AUTOSAR XML (schema 4-3-0)
package /E3_1_2_Premium
  system System
    system mapping Mapping_TestSwc_RGS_VL_Data
      data-mappings:
        data-element=Geltungsbereich_E3_1_2_Premium.R_RGS_Nachlauf_allg.RGS_Nachlauf_allg, system-signal=RGS_Nachlauf_allg
        data-element=Geltungsbereich_E3_1_2_Premium.R_RGS_VL_Nachlauf_2.RGS_VL_Nachlauf_2, system-signal=RGS_VL_Nachlauf_2
        data-element=Geltungsbereich_E3_1_2_Premium.R_NM_Airbag_01_FCAB.NM_Airbag_01_FCAB, system-signal=NM_Airbag_01_FCAB
        data-element=Geltungsbereich_E3_1_2_Premium.R_RGS_VL_Anforderung.RGS_VL_Anforderung, system-signal=RGS_VL_Anforderung
        data-element=Geltungsbereich_E3_1_2_Premium.P_RGS_VL_KD_Fehler.RGS_VL_KD_Fehler, system-signal=RGS_VL_KD_Fehler
        data-element=Geltungsbereich_E3_1_2_Premium.P_NM_RGS_VL_NM_aktiv_KL15.NM_RGS_VL_NM_aktiv_KL15, system-signal=NM_RGS_VL_NM_aktiv_KL15
        data-element=Geltungsbereich_E3_1_2_Premium.P_NM_RGS_VL_CBV_AWB.NM_RGS_VL_CBV_AWB, system-signal=NM_RGS_VL_CBV_AWB
        data-element=Geltungsbereich_E3_1_2_Premium.P_NM_RGS_VL_NM_aktiv_Tmin.NM_RGS_VL_NM_aktiv_Tmin, system-signal=NM_RGS_VL_NM_aktiv_Tmin
        data-element=Geltungsbereich_E3_1_2_Premium.P_NM_RGS_VL_CBV_CRI.NM_RGS_VL_CBV_CRI, system-signal=NM_RGS_VL_CBV_CRI
        data-element=Geltungsbereich_E3_1_2_Premium.P_NM_RGS_VL_UDS_CC.NM_RGS_VL_UDS_CC, system-signal=NM_RGS_VL_UDS_CC
        data-element=Geltungsbereich_E3_1_2_Premium.P_NM_RGS_VL_NM_State.NM_RGS_VL_NM_State, system-signal=NM_RGS_VL_NM_State
        data-element=Geltungsbereich_E3_1_2_Premium.P_RGS_VL_Lokalaktiv.RGS_VL_Lokalaktiv, system-signal=RGS_VL_Lokalaktiv
        data-element=Geltungsbereich_E3_1_2_Premium.P_RGS_VL_KompSchutz.RGS_VL_KompSchutz, system-signal=RGS_VL_KompSchutz
        data-element=Geltungsbereich_E3_1_2_Premium.P_RGS_VL_Abschaltstufe.RGS_VL_Abschaltstufe, system-signal=RGS_VL_Abschaltstufe
        data-element=Geltungsbereich_E3_1_2_Premium.P_NM_RGS_VL_Wakeup.NM_RGS_VL_Wakeup, system-signal=NM_RGS_VL_Wakeup
        data-element=Geltungsbereich_E3_1_2_Premium.P_RGS_VL_Subsystemaktiv.RGS_VL_Subsystemaktiv, system-signal=RGS_VL_Subsystemaktiv
        data-element=Geltungsbereich_E3_1_2_Premium.P_RGS_VL_Transport_Mode.RGS_VL_Transport_Mode, system-signal=RGS_VL_Transport_Mode
        data-element=Geltungsbereich_E3_1_2_Premium.P_RGS_VL_Nachlauftyp.RGS_VL_Nachlauftyp, system-signal=RGS_VL_Nachlauftyp
        data-element=Geltungsbereich_E3_1_2_Premium.P_RGS_VL_Gurtgeschwindigkeit.RGS_VL_Gurtgeschwindigkeit, system-signal=RGS_VL_Gurtgeschwindigkeit
        data-element=Geltungsbereich_E3_1_2_Premium.P_RGS_VL_Gurtbandauszug.RGS_VL_Gurtbandauszug, system-signal=RGS_VL_Gurtbandauszug
        data-element=Geltungsbereich_E3_1_2_Premium.P_NM_RGS_VL_NM_aktiv_Mot_aktiv.NM_RGS_VL_NM_aktiv_Mot_aktiv, system-signal=NM_RGS_VL_NM_aktiv_Mot_aktiv
        data-element=Geltungsbereich_E3_1_2_Premium.P_NM_RGS_VL_NM_aktiv_Diag.NM_RGS_VL_NM_aktiv_Diag, system-signal=NM_RGS_VL_NM_aktiv_Diag
        data-element=Geltungsbereich_E3_1_2_Premium.P_NM_RGS_VL_FCIB.NM_RGS_VL_FCIB, system-signal=NM_RGS_VL_FCIB
        data-element=Geltungsbereich_E3_1_2_Premium.P_NM_RGS_VL_FCAB.NM_RGS_VL_FCAB, system-signal=NM_RGS_VL_FCAB
        data-element=Geltungsbereich_E3_1_2_Premium.P_RGS_VL_SNI_10.RGS_VL_SNI_10, system-signal=RGS_VL_SNI_10
        data-element=Geltungsbereich_E3_1_2_Premium.P_KN_RGS_VL_ECUKnockOutTimer.KN_RGS_VL_ECUKnockOutTimer, system-signal=KN_RGS_VL_ECUKnockOutTimer
        data-element=Geltungsbereich_E3_1_2_Premium.P_KN_RGS_VL_BusKnockOut.KN_RGS_VL_BusKnockOut, system-signal=KN_RGS_VL_BusKnockOut
        data-element=Geltungsbereich_E3_1_2_Premium.P_KN_RGS_VL_ECUKnockOut.KN_RGS_VL_ECUKnockOut, system-signal=KN_RGS_VL_ECUKnockOut
        data-element=Geltungsbereich_E3_1_2_Premium.P_KN_RGS_VL_BusKnockOutTimer.KN_RGS_VL_BusKnockOutTimer, system-signal=KN_RGS_VL_BusKnockOutTimer
        data-element=Geltungsbereich_E3_1_2_Premium.P_NM_RGS_VL_SNI_10.NM_RGS_VL_SNI_10, system-signal=NM_RGS_VL_SNI_10
        data-element=Geltungsbereich_E3_1_2_Premium.P_RGS_VL_keineStraffungUnterspg.RGS_VL_keineStraffungUnterspg, system-signal=RGS_VL_keineStraffungUnterspg
        data-element=Geltungsbereich_E3_1_2_Premium.P_RGS_VL_nicht_programmiert.RGS_VL_nicht_programmiert, system-signal=RGS_VL_nicht_programmiert
        data-element=Geltungsbereich_E3_1_2_Premium.P_RGS_VL_Uebertemperatur_defekt.RGS_VL_Uebertemperatur_defekt, system-signal=RGS_VL_Uebertemperatur_defekt
        data-element=Geltungsbereich_E3_1_2_Premium.P_RGS_VL_Bauteilfehler.RGS_VL_Bauteilfehler, system-signal=RGS_VL_Bauteilfehler
        data-element=Geltungsbereich_E3_1_2_Premium.P_RGS_VL_keineStraffungUeberspg.RGS_VL_keineStraffungUeberspg, system-signal=RGS_VL_keineStraffungUeberspg
        data-element=Geltungsbereich_E3_1_2_Premium.P_RGS_VL_Max_Gurtlosezyklen.RGS_VL_Max_Gurtlosezyklen, system-signal=RGS_VL_Max_Gurtlosezyklen
        data-element=Geltungsbereich_E3_1_2_Premium.P_RGS_VL_Temp.RGS_VL_Temp, system-signal=RGS_VL_Temp
        data-element=Geltungsbereich_E3_1_2_Premium.P_RGS_VL_Kommunikationsfehler_ASG.RGS_VL_Kommunikationsfehler_ASG, system-signal=RGS_VL_Kommunikationsfehler_ASG
        data-element=Geltungsbereich_E3_1_2_Premium.P_RGS_VL_Unterspannung.RGS_VL_Unterspannung, system-signal=RGS_VL_Unterspannung
        data-element=Geltungsbereich_E3_1_2_Premium.P_RGS_VL_Max_Straffzyklenfehler.RGS_VL_Max_Straffzyklenfehler, system-signal=RGS_VL_Max_Straffzyklenfehler
        data-element=Geltungsbereich_E3_1_2_Premium.P_RGS_VL_Max_Haptikzyklenfehler.RGS_VL_Max_Haptikzyklenfehler, system-signal=RGS_VL_Max_Haptikzyklenfehler
        data-element=Geltungsbereich_E3_1_2_Premium.P_RGS_VL_Crashabschaltung.RGS_VL_Crashabschaltung, system-signal=RGS_VL_Crashabschaltung
        data-element=Geltungsbereich_E3_1_2_Premium.P_RGS_VL_Ueberspannung.RGS_VL_Ueberspannung, system-signal=RGS_VL_Ueberspannung
        data-element=Geltungsbereich_E3_1_2_Premium.P_RGS_VL_Motorfehler.RGS_VL_Motorfehler, system-signal=RGS_VL_Motorfehler
        data-element=Geltungsbereich_E3_1_2_Premium.P_RGS_VL_EEPROM_Datensatzfehler.RGS_VL_EEPROM_Datensatzfehler, system-signal=RGS_VL_EEPROM_Datensatzfehler
        data-element=Geltungsbereich_E3_1_2_Premium.P_RGS_VL_InPos.RGS_VL_InPos, system-signal=RGS_VL_InPos
        data-element=Geltungsbereich_E3_1_2_Premium.P_RGS_VL_Strom.RGS_VL_Strom, system-signal=RGS_VL_Strom
        data-element=Geltungsbereich_E3_1_2_Premium.P_RGS_VL_Status.RGS_VL_Status, system-signal=RGS_VL_Status
package /ComponentTypes
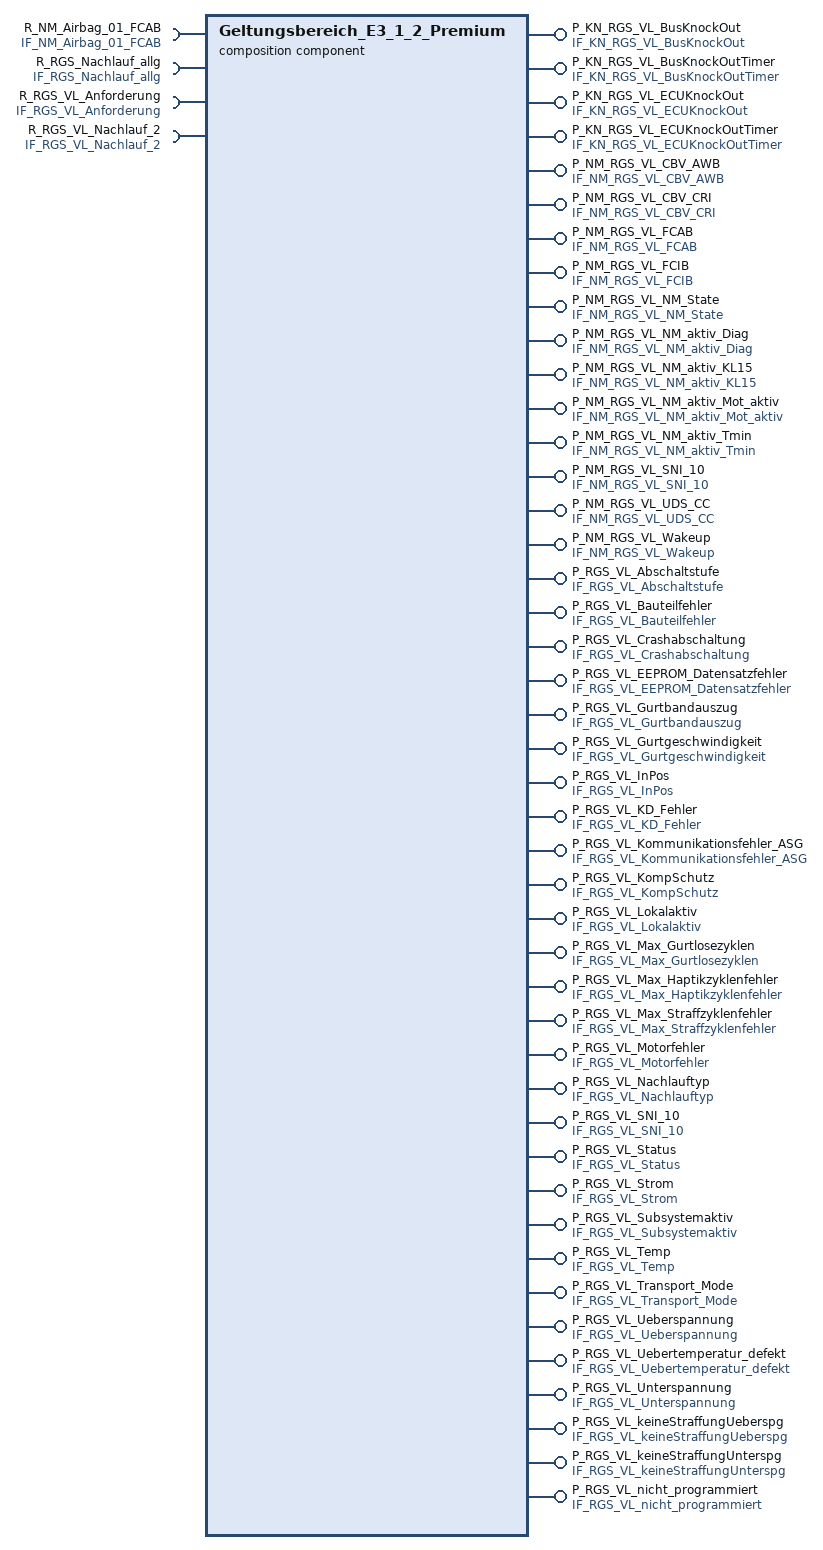
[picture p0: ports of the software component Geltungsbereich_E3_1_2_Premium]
  composition sw component type Geltungsbereich_E3_1_2_Premium
    44 x provide port:
      P_KN_RGS_VL_BusKnockOut: nonqueued-sender-com-spec{data-element=KN_RGS_VL_BusKnockOut, handle-out-of-range=DEFAULT, init-value=constant-reference=Init_KN_RGS_VL_BusKnockOut}, provided-interface=IF_KN_RGS_VL_BusKnockOut
      P_KN_RGS_VL_BusKnockOutTimer: nonqueued-sender-com-spec{data-element=KN_RGS_VL_BusKnockOutTimer, handle-out-of-range=DEFAULT, init-value=constant-reference=Init_KN_RGS_VL_BusKnockOutTimer}, provided-interface=IF_KN_RGS_VL_BusKnockOutTimer
      P_KN_RGS_VL_ECUKnockOut: nonqueued-sender-com-spec{data-element=KN_RGS_VL_ECUKnockOut, handle-out-of-range=DEFAULT, init-value=constant-reference=Init_KN_RGS_VL_ECUKnockOut}, provided-interface=IF_KN_RGS_VL_ECUKnockOut
      P_KN_RGS_VL_ECUKnockOutTimer: nonqueued-sender-com-spec{data-element=KN_RGS_VL_ECUKnockOutTimer, handle-out-of-range=DEFAULT, init-value=constant-reference=Init_KN_RGS_VL_ECUKnockOutTimer}, provided-interface=IF_KN_RGS_VL_ECUKnockOutTimer
      P_NM_RGS_VL_CBV_AWB: nonqueued-sender-com-spec{data-element=NM_RGS_VL_CBV_AWB, handle-out-of-range=DEFAULT, init-value=constant-reference=Init_NM_RGS_VL_CBV_AWB}, provided-interface=IF_NM_RGS_VL_CBV_AWB
      P_NM_RGS_VL_CBV_CRI: nonqueued-sender-com-spec{data-element=NM_RGS_VL_CBV_CRI, handle-out-of-range=DEFAULT, init-value=constant-reference=Init_NM_RGS_VL_CBV_CRI}, provided-interface=IF_NM_RGS_VL_CBV_CRI
      P_NM_RGS_VL_FCAB: nonqueued-sender-com-spec{data-element=NM_RGS_VL_FCAB, handle-out-of-range=DEFAULT, init-value=constant-reference=Init_NM_RGS_VL_FCAB}, provided-interface=IF_NM_RGS_VL_FCAB
      P_NM_RGS_VL_FCIB: nonqueued-sender-com-spec{data-element=NM_RGS_VL_FCIB, handle-out-of-range=DEFAULT, init-value=constant-reference=Init_NM_RGS_VL_FCIB}, provided-interface=IF_NM_RGS_VL_FCIB
      P_NM_RGS_VL_NM_State: nonqueued-sender-com-spec{data-element=NM_RGS_VL_NM_State, handle-out-of-range=DEFAULT, init-value=constant-reference=Init_NM_RGS_VL_NM_State}, provided-interface=IF_NM_RGS_VL_NM_State
      P_NM_RGS_VL_NM_aktiv_Diag: nonqueued-sender-com-spec{data-element=NM_RGS_VL_NM_aktiv_Diag, handle-out-of-range=DEFAULT, init-value=constant-reference=Init_NM_RGS_VL_NM_aktiv_Diag}, provided-interface=IF_NM_RGS_VL_NM_aktiv_Diag
      P_NM_RGS_VL_NM_aktiv_KL15: nonqueued-sender-com-spec{data-element=NM_RGS_VL_NM_aktiv_KL15, handle-out-of-range=DEFAULT, init-value=constant-reference=Init_NM_RGS_VL_NM_aktiv_KL15}, provided-interface=IF_NM_RGS_VL_NM_aktiv_KL15
      P_NM_RGS_VL_NM_aktiv_Mot_aktiv: nonqueued-sender-com-spec{data-element=NM_RGS_VL_NM_aktiv_Mot_aktiv, handle-out-of-range=DEFAULT, init-value=constant-reference=Init_NM_RGS_VL_NM_aktiv_Mot_aktiv}, provided-interface=IF_NM_RGS_VL_NM_aktiv_Mot_aktiv
      P_NM_RGS_VL_NM_aktiv_Tmin: nonqueued-sender-com-spec{data-element=NM_RGS_VL_NM_aktiv_Tmin, handle-out-of-range=DEFAULT, init-value=constant-reference=Init_NM_RGS_VL_NM_aktiv_Tmin}, provided-interface=IF_NM_RGS_VL_NM_aktiv_Tmin
      P_NM_RGS_VL_SNI_10: nonqueued-sender-com-spec{data-element=NM_RGS_VL_SNI_10, handle-out-of-range=DEFAULT, init-value=constant-reference=Init_NM_RGS_VL_SNI_10}, provided-interface=IF_NM_RGS_VL_SNI_10
      P_NM_RGS_VL_UDS_CC: nonqueued-sender-com-spec{data-element=NM_RGS_VL_UDS_CC, handle-out-of-range=DEFAULT, init-value=constant-reference=Init_NM_RGS_VL_UDS_CC}, provided-interface=IF_NM_RGS_VL_UDS_CC
      P_NM_RGS_VL_Wakeup: nonqueued-sender-com-spec{data-element=NM_RGS_VL_Wakeup, handle-out-of-range=DEFAULT, init-value=constant-reference=Init_NM_RGS_VL_Wakeup}, provided-interface=IF_NM_RGS_VL_Wakeup
      P_RGS_VL_Abschaltstufe: nonqueued-sender-com-spec{data-element=RGS_VL_Abschaltstufe, handle-out-of-range=DEFAULT, init-value=constant-reference=Init_RGS_VL_Abschaltstufe}, provided-interface=IF_RGS_VL_Abschaltstufe
      P_RGS_VL_Bauteilfehler: nonqueued-sender-com-spec{data-element=RGS_VL_Bauteilfehler, handle-out-of-range=DEFAULT, init-value=constant-reference=Init_RGS_VL_Bauteilfehler}, provided-interface=IF_RGS_VL_Bauteilfehler
      P_RGS_VL_Crashabschaltung: nonqueued-sender-com-spec{data-element=RGS_VL_Crashabschaltung, handle-out-of-range=DEFAULT, init-value=constant-reference=Init_RGS_VL_Crashabschaltung}, provided-interface=IF_RGS_VL_Crashabschaltung
      P_RGS_VL_EEPROM_Datensatzfehler: nonqueued-sender-com-spec{data-element=RGS_VL_EEPROM_Datensatzfehler, handle-out-of-range=DEFAULT, init-value=constant-reference=Init_RGS_VL_EEPROM_Datensatzfehler}, provided-interface=IF_RGS_VL_EEPROM_Datensatzfehler
      P_RGS_VL_Gurtbandauszug: nonqueued-sender-com-spec{data-element=RGS_VL_Gurtbandauszug, handle-out-of-range=DEFAULT, init-value=constant-reference=Init_RGS_VL_Gurtbandauszug}, provided-interface=IF_RGS_VL_Gurtbandauszug
      P_RGS_VL_Gurtgeschwindigkeit: nonqueued-sender-com-spec{data-element=RGS_VL_Gurtgeschwindigkeit, handle-out-of-range=DEFAULT, init-value=constant-reference=Init_RGS_VL_Gurtgeschwindigkeit}, provided-interface=IF_RGS_VL_Gurtgeschwindigkeit
      P_RGS_VL_InPos: nonqueued-sender-com-spec{data-element=RGS_VL_InPos, handle-out-of-range=DEFAULT, init-value=constant-reference=Init_RGS_VL_InPos}, provided-interface=IF_RGS_VL_InPos
      P_RGS_VL_KD_Fehler: nonqueued-sender-com-spec{data-element=RGS_VL_KD_Fehler, handle-out-of-range=DEFAULT, init-value=constant-reference=Init_RGS_VL_KD_Fehler}, provided-interface=IF_RGS_VL_KD_Fehler
      P_RGS_VL_Kommunikationsfehler_ASG: nonqueued-sender-com-spec{data-element=RGS_VL_Kommunikationsfehler_ASG, handle-out-of-range=DEFAULT, init-value=constant-reference=Init_RGS_VL_Kommunikationsfehler_ASG}, provided-interface=IF_RGS_VL_Kommunikationsfehler_ASG
      P_RGS_VL_KompSchutz: nonqueued-sender-com-spec{data-element=RGS_VL_KompSchutz, handle-out-of-range=DEFAULT, init-value=constant-reference=Init_RGS_VL_KompSchutz}, provided-interface=IF_RGS_VL_KompSchutz
      P_RGS_VL_Lokalaktiv: nonqueued-sender-com-spec{data-element=RGS_VL_Lokalaktiv, handle-out-of-range=DEFAULT, init-value=constant-reference=Init_RGS_VL_Lokalaktiv}, provided-interface=IF_RGS_VL_Lokalaktiv
      P_RGS_VL_Max_Gurtlosezyklen: nonqueued-sender-com-spec{data-element=RGS_VL_Max_Gurtlosezyklen, handle-out-of-range=DEFAULT, init-value=constant-reference=Init_RGS_VL_Max_Gurtlosezyklen}, provided-interface=IF_RGS_VL_Max_Gurtlosezyklen
      P_RGS_VL_Max_Haptikzyklenfehler: nonqueued-sender-com-spec{data-element=RGS_VL_Max_Haptikzyklenfehler, handle-out-of-range=DEFAULT, init-value=constant-reference=Init_RGS_VL_Max_Haptikzyklenfehler}, provided-interface=IF_RGS_VL_Max_Haptikzyklenfehler
      P_RGS_VL_Max_Straffzyklenfehler: nonqueued-sender-com-spec{data-element=RGS_VL_Max_Straffzyklenfehler, handle-out-of-range=DEFAULT, init-value=constant-reference=Init_RGS_VL_Max_Straffzyklenfehler}, provided-interface=IF_RGS_VL_Max_Straffzyklenfehler
      P_RGS_VL_Motorfehler: nonqueued-sender-com-spec{data-element=RGS_VL_Motorfehler, handle-out-of-range=DEFAULT, init-value=constant-reference=Init_RGS_VL_Motorfehler}, provided-interface=IF_RGS_VL_Motorfehler
      P_RGS_VL_Nachlauftyp: nonqueued-sender-com-spec{data-element=RGS_VL_Nachlauftyp, handle-out-of-range=DEFAULT, init-value=constant-reference=Init_RGS_VL_Nachlauftyp}, provided-interface=IF_RGS_VL_Nachlauftyp
      P_RGS_VL_SNI_10: nonqueued-sender-com-spec{data-element=RGS_VL_SNI_10, handle-out-of-range=DEFAULT, init-value=constant-reference=Init_RGS_VL_SNI_10}, provided-interface=IF_RGS_VL_SNI_10
      P_RGS_VL_Status: nonqueued-sender-com-spec{data-element=RGS_VL_Status, handle-out-of-range=DEFAULT, init-value=constant-reference=Init_RGS_VL_Status}, provided-interface=IF_RGS_VL_Status
      P_RGS_VL_Strom: nonqueued-sender-com-spec{data-element=RGS_VL_Strom, handle-out-of-range=DEFAULT, init-value=constant-reference=Init_RGS_VL_Strom}, provided-interface=IF_RGS_VL_Strom
      P_RGS_VL_Subsystemaktiv: nonqueued-sender-com-spec{data-element=RGS_VL_Subsystemaktiv, handle-out-of-range=DEFAULT, init-value=constant-reference=Init_RGS_VL_Subsystemaktiv}, provided-interface=IF_RGS_VL_Subsystemaktiv
      P_RGS_VL_Temp: nonqueued-sender-com-spec{data-element=RGS_VL_Temp, handle-out-of-range=DEFAULT, init-value=constant-reference=Init_RGS_VL_Temp}, provided-interface=IF_RGS_VL_Temp
      P_RGS_VL_Transport_Mode: nonqueued-sender-com-spec{data-element=RGS_VL_Transport_Mode, handle-out-of-range=DEFAULT, init-value=constant-reference=Init_RGS_VL_Transport_Mode}, provided-interface=IF_RGS_VL_Transport_Mode
      P_RGS_VL_Ueberspannung: nonqueued-sender-com-spec{data-element=RGS_VL_Ueberspannung, handle-out-of-range=DEFAULT, init-value=constant-reference=Init_RGS_VL_Ueberspannung}, provided-interface=IF_RGS_VL_Ueberspannung
      P_RGS_VL_Uebertemperatur_defekt: nonqueued-sender-com-spec{data-element=RGS_VL_Uebertemperatur_defekt, handle-out-of-range=DEFAULT, init-value=constant-reference=Init_RGS_VL_Uebertemperatur_defekt}, provided-interface=IF_RGS_VL_Uebertemperatur_defekt
      P_RGS_VL_Unterspannung: nonqueued-sender-com-spec{data-element=RGS_VL_Unterspannung, handle-out-of-range=DEFAULT, init-value=constant-reference=Init_RGS_VL_Unterspannung}, provided-interface=IF_RGS_VL_Unterspannung
      P_RGS_VL_keineStraffungUeberspg: nonqueued-sender-com-spec{data-element=RGS_VL_keineStraffungUeberspg, handle-out-of-range=DEFAULT, init-value=constant-reference=Init_RGS_VL_keineStraffungUeberspg}, provided-interface=IF_RGS_VL_keineStraffungUeberspg
      P_RGS_VL_keineStraffungUnterspg: nonqueued-sender-com-spec{data-element=RGS_VL_keineStraffungUnterspg, handle-out-of-range=DEFAULT, init-value=constant-reference=Init_RGS_VL_keineStraffungUnterspg}, provided-interface=IF_RGS_VL_keineStraffungUnterspg
      P_RGS_VL_nicht_programmiert: nonqueued-sender-com-spec{data-element=RGS_VL_nicht_programmiert, handle-out-of-range=DEFAULT, init-value=constant-reference=Init_RGS_VL_nicht_programmiert}, provided-interface=IF_RGS_VL_nicht_programmiert
    4 x require port:
      R_NM_Airbag_01_FCAB: nonqueued-receiver-com-spec{data-element=NM_Airbag_01_FCAB, handle-out-of-range=DEFAULT, alive-timeout=2.0, enable-update=true, init-value=constant-reference=Init_NM_Airbag_01_FCAB}, required-interface=IF_NM_Airbag_01_FCAB
      R_RGS_Nachlauf_allg: nonqueued-receiver-com-spec{data-element=RGS_Nachlauf_allg, handle-out-of-range=DEFAULT, alive-timeout=5.0, enable-update=true, init-value=constant-reference=Init_RGS_Nachlauf_allg}, required-interface=IF_RGS_Nachlauf_allg
      R_RGS_VL_Anforderung: nonqueued-receiver-com-spec{data-element=RGS_VL_Anforderung, handle-out-of-range=DEFAULT, alive-timeout=5.0, enable-update=true, init-value=constant-reference=Init_RGS_VL_Anforderung}, required-interface=IF_RGS_VL_Anforderung
      R_RGS_VL_Nachlauf_2: nonqueued-receiver-com-spec{data-element=RGS_VL_Nachlauf_2, handle-out-of-range=DEFAULT, alive-timeout=5.0, enable-update=true, init-value=constant-reference=Init_RGS_VL_Nachlauf_2}, required-interface=IF_RGS_VL_Nachlauf_2
